CM_ "IMPORT _subaru_global.dbc";

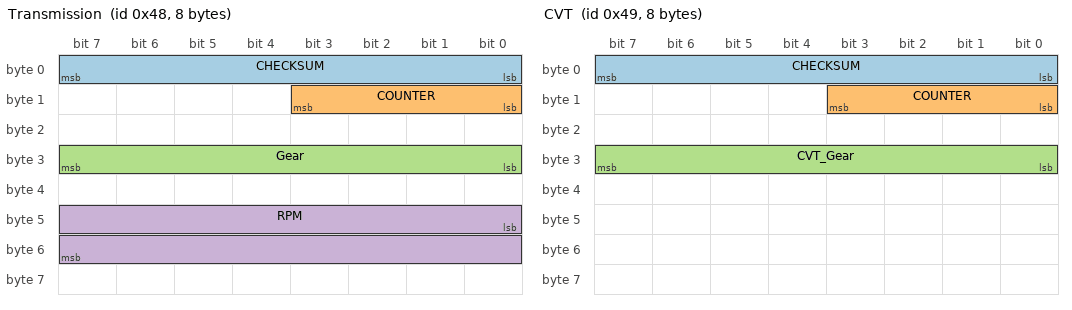
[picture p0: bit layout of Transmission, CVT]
BO_ 72 Transmission: 8 XXX
 SG_ CHECKSUM : 0|8@1+ (1,0) [0|255] "" XXX
 SG_ COUNTER : 8|4@1+ (1,0) [0|15] "" XXX
 SG_ Gear : 24|8@1+ (1,0) [0|255] "" XXX
 SG_ RPM : 40|16@1+ (1,0) [0|65535] "" XXX

BO_ 73 CVT: 8 XXX
 SG_ CHECKSUM : 0|8@1+ (1,0) [0|255] "" XXX
 SG_ COUNTER : 8|4@1+ (1,0) [0|15] "" XXX
 SG_ CVT_Gear : 24|8@1+ (1,0) [0|255] "" XXX

BO_ 545 ES_Distance: 8 XXX
 SG_ CHECKSUM : 0|8@1+ (1,0) [0|255] "" XXX
 SG_ COUNTER : 8|4@1+ (1,0) [0|15] "" XXX
 SG_ Signal1 : 12|3@1+ (1,0) [0|7] "" XXX
 SG_ Cruise_Fault : 15|1@1+ (1,0) [0|1] "" XXX
 SG_ Cruise_Throttle : 16|12@1+ (1,0) [0|4095] "" XXX
 SG_ Signal2 : 28|4@1+ (1,0) [0|15] "" XXX
 SG_ Car_Follow : 32|1@1+ (1,0) [0|1] "" XXX
 SG_ Signal3 : 33|1@1+ (1,0) [0|1] "" XXX
 SG_ Cruise_Soft_Disable : 34|1@1+ (1,0) [0|1] "" XXX
 SG_ Signal7 : 35|1@1+ (1,0) [0|1] "" XXX
 SG_ Cruise_Brake_Active : 36|1@1+ (1,0) [0|1] "" XXX
 SG_ Distance_Swap : 37|1@1+ (1,0) [0|1] "" XXX
 SG_ Cruise_EPB : 38|1@1+ (1,0) [0|1] "" XXX
 SG_ Signal4 : 39|1@0+ (1,0) [0|1] "" XXX
 SG_ Close_Distance : 40|8@1+ (0.019607,0) [0|5] "m" XXX
 SG_ Signal5 : 48|8@1+ (1,0) [0|1] "" XXX
 SG_ Cruise_Cancel : 56|1@1+ (1,0) [0|1] "" XXX
 SG_ Cruise_Set : 57|1@1+ (1,0) [0|1] "" XXX
 SG_ Cruise_Resume : 58|1@1+ (1,0) [0|1] "" XXX
 SG_ Signal6 : 59|5@1+ (1,0) [0|1] "" XXX

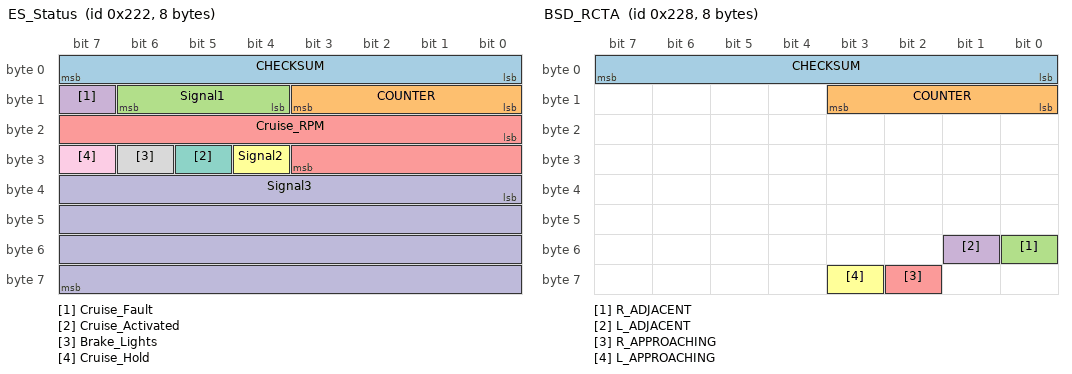
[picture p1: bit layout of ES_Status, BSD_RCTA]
BO_ 546 ES_Status: 8 XXX
 SG_ CHECKSUM : 0|8@1+ (1,0) [0|255] "" XXX
 SG_ COUNTER : 8|4@1+ (1,0) [0|15] "" XXX
 SG_ Signal1 : 12|3@1+ (1,0) [0|1] "" XXX
 SG_ Cruise_Fault : 15|1@1+ (1,0) [0|1] "" XXX
 SG_ Cruise_RPM : 16|12@1+ (1,0) [0|4095] "" XXX
 SG_ Signal2 : 28|1@0+ (1,0) [0|1] "" XXX
 SG_ Cruise_Activated : 29|1@0+ (1,0) [0|1] "" XXX
 SG_ Brake_Lights : 30|1@1+ (1,0) [0|1] "" XXX
 SG_ Cruise_Hold : 31|1@1+ (1,0) [0|1] "" XXX
 SG_ Signal3 : 32|32@1+ (1,0) [0|1] "" XXX

BO_ 552 BSD_RCTA: 8 XXX
 SG_ CHECKSUM : 0|8@1+ (1,0) [0|255] "" XXX
 SG_ COUNTER : 8|4@1+ (1,0) [0|15] "" XXX
 SG_ R_ADJACENT : 48|1@1+ (1,0) [0|1] "" XXX
 SG_ L_ADJACENT : 49|1@1+ (1,0) [0|1] "" XXX
 SG_ R_APPROACHING : 58|1@1+ (1,0) [0|1] "" XXX
 SG_ L_APPROACHING : 59|1@1+ (1,0) [0|1] "" XXX

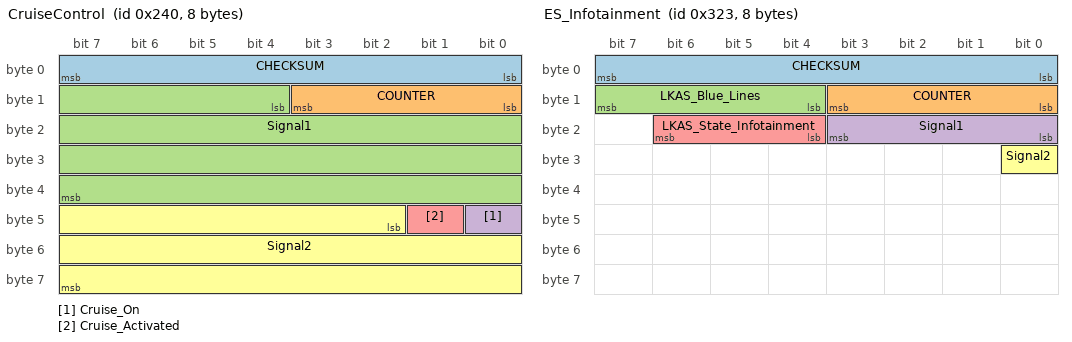
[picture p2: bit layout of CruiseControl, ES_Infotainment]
BO_ 576 CruiseControl: 8 XXX
 SG_ CHECKSUM : 0|8@1+ (1,0) [0|255] "" XXX
 SG_ COUNTER : 8|4@1+ (1,0) [0|15] "" XXX
 SG_ Signal1 : 12|28@1+ (1,0) [0|268435455] "" XXX
 SG_ Cruise_On : 40|1@1+ (1,0) [0|1] "" XXX
 SG_ Cruise_Activated : 41|1@1+ (1,0) [0|1] "" XXX
 SG_ Signal2 : 42|22@1+ (1,0) [0|4194303] "" XXX

BO_ 803 ES_Infotainment: 8 XXX
 SG_ CHECKSUM : 0|8@1+ (1,0) [0|255] "" XXX
 SG_ COUNTER : 8|4@1+ (1,0) [0|15] "" XXX
 SG_ LKAS_Blue_Lines : 15|4@0+ (1,0) [0|15] "" XXX
 SG_ Signal1 : 19|4@0+ (1,0) [0|15] "" XXX
 SG_ LKAS_State_Infotainment : 22|3@0+ (1,0) [0|7] "" XXX
 SG_ Signal2 : 24|1@0+ (1,0) [0|1] "" XXX

CM_ SG_ 545 Cruise_Throttle "RPM-like output signal";
CM_ SG_ 545 Cruise_EPB "1 = Electric Parking Brake set";
CM_ SG_ 545 Distance_Swap "Switch from Close to Far distance";
CM_ SG_ 545 Cruise_Soft_Disable "Eyesight Temporary disable, sets CruiseControl Activated = 0";
CM_ SG_ 546 Cruise_RPM "ES RPM output for ECM and TCM";
CM_ SG_ 546 Signal3 "0 when cruise_activated = 1";
CM_ SG_ 803 Signal1 "Seems to be static, set only on some cars";
CM_ SG_ 803 Signal2 "Seems to be static, set only on some cars";
VAL_ 803 LKAS_Blue_Lines 0 "no modifier" 2 "changes lines to blue";
VAL_ 803 LKAS_State_Infotainment 0 "none" 2 "Obstacle Detected" 3 "Keep Hands On Wheel" 4 "Keep Hands On Wheel Off";
VAL_ 72 Gear 2 "N" 3 "R" 4 "P" 121 "D" 137 "1" 145 "2" 153 "3" 161 "4" 169 "5" 177 "6";
